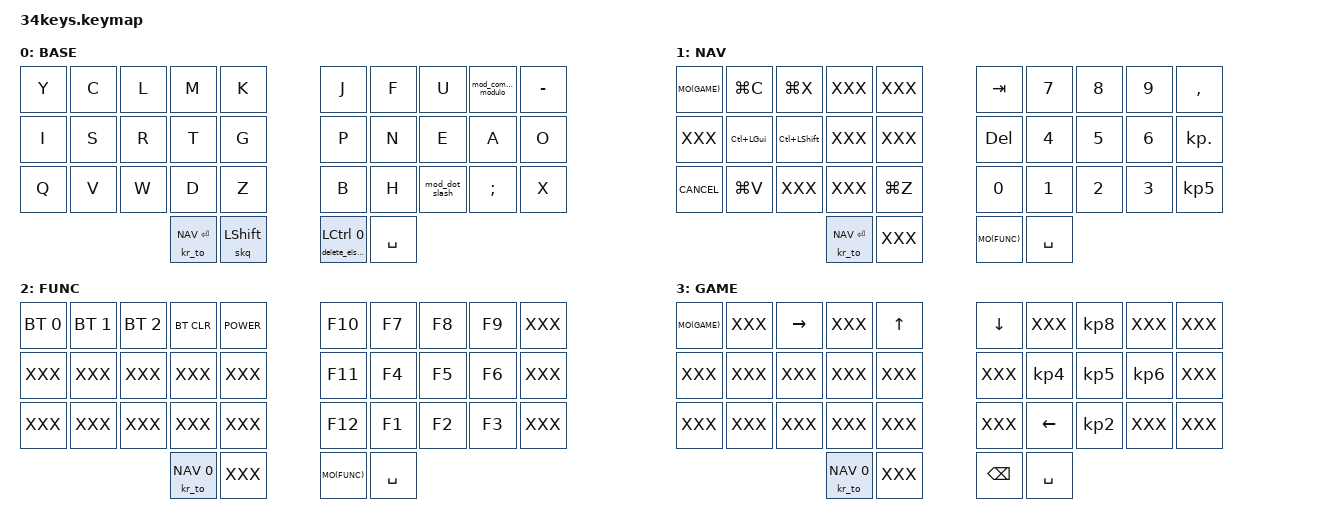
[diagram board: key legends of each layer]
#include <behaviors.dtsi>
#include <dt-bindings/zmk/keys.h>
#include <dt-bindings/zmk/bt.h>
#include <dt-bindings/zmk/outputs.h>
#include <dt-bindings/zmk/mouse.h>
#include <dt-bindings/zmk/mouse_settings.h>
#include "34keys.h"
#include "mouse_keys.dtsi"

&sk {
  release-after-ms = <STICKY_KEY_TIMEOUT>;
};

&caps_word {
  continue-list = <UNDERSCORE MINUS BACKSPACE>;
};

/ {

  combos {
    #include "combos.dtsi"
  };

  macros {
   #include "macros.dtsi"
  };

  behaviors {
    #include "behaviorsfs.dtsi"
  };

  keymap {
    compatible = "zmk,keymap";

    base_layer {
      label = "BASE";
      bindings = <
// ╭─────────────┬─────────────┬─────────────┬─────────────┬─────────────╮   ╭─────────────┬─────────────┬─────────────┬─────────────┬─────────────╮
        &kp Y         &kp C         &kp L         &kp M         &kp K             &kp J         &kp F         &kp U         &mod_comma_modulo	&kp MINUS
// ├─────────────┼─────────────┼─────────────┼─────────────┼─────────────┤   ├─────────────┼─────────────┼─────────────┼─────────────┼─────────────┤
        &kp I         &kp S         &kp R         &kp T         &kp G             &kp P         &kp N         &kp E         &kp A         &kp O
// ├─────────────┼─────────────┼─────────────┼─────────────┼─────────────┤   ├─────────────┼─────────────┼─────────────┼─────────────┼─────────────┤
        &kp Q         &kp V         &kp W         &kp D         &kp Z             &kp B         &kp H         &mod_dot_slash &kp SEMI      &kp X
// ╰─────────────┴─────────────┴─────────────┼─────────────┼─────────────┤   ├─────────────┼─────────────┼─────────────┴─────────────┴─────────────╯
                                                &kr_to NAV ENTER   &skq LSHIFT       &delete_else_hold LCTRL 0 &kp SPACE
//                                           ╰─────────────┴─────────────╯   ╰─────────────┴─────────────╯
      >;
    };

    nav_layer {
      label = "NAV";
      bindings = <
// ╭─────────────┬─────────────┬─────────────┬─────────────┬─────────────╮   ╭─────────────┬─────────────┬─────────────┬─────────────┬─────────────╮
        MO(GAME)     &kp LG(C)			&kp LG(X)           XXX			XXX 			&kp TAB       &kp N7         &kp N8        &kp N9         &kp COMMA
// ├─────────────┼─────────────┼─────────────┼─────────────┼─────────────┤   ├─────────────┼─────────────┼─────────────┼─────────────┼─────────────┤
        XXX          &kp LC(LGUI) 	&kp LC(LSHFT) XXX     		XXX 			&kp DEL       &kp N4         &kp N5        &kp N6         &kp KP_DOT
// ├─────────────┼─────────────┼─────────────┼─────────────┼─────────────┤   ├─────────────┼─────────────┼─────────────┼─────────────┼─────────────┤
        &kp K_CANCEL  &kp LG(V)			XXX       	  XXX           &kp LG(Z) 		    &kp N0        &kp N1         &kp N2        &kp N3         &kp KP_N5
// ╰─────────────┴─────────────┴─────────────┼─────────────┼─────────────┤   ├─────────────┼─────────────┼─────────────┴─────────────┴─────────────╯
                                                &kr_to NAV ENTER    XXX               MO(FUNC)      &kp SPACE
//                                           ╰─────────────┴─────────────╯   ╰─────────────┴─────────────╯
      >;
    };

func_layer {
      label = "FUNC";
      bindings = <
// ╭─────────────┬─────────────┬─────────────┬─────────────┬─────────────╮   ╭─────────────┬─────────────┬─────────────┬─────────────┬─────────────╮
        &bt BT_SEL 0  &bt BT_SEL 1  &bt BT_SEL 2  &bt BT_CLR    &kp C_POWER       &kp F10       &kp F7         &kp F8        &kp F9        XXX
// ├─────────────┼─────────────┼─────────────┼─────────────┼─────────────┤   ├─────────────┼─────────────┼─────────────┼─────────────┼─────────────┤
        XXX           XXX           XXX           XXX           XXX               &kp F11       &kp F4         &kp F5        &kp F6        XXX
// ├─────────────┼─────────────┼─────────────┼─────────────┼─────────────┤   ├─────────────┼─────────────┼─────────────┼─────────────┼─────────────┤
        XXX           XXX           XXX           XXX           XXX               &kp F12       &kp F1         &kp F2        &kp F3        XXX
// ╰─────────────┴─────────────┴─────────────┼─────────────┼─────────────┤   ├─────────────┼─────────────┼─────────────┴─────────────┴─────────────╯
                                                &kr_to NAV 0    XXX               MO(FUNC)      &kp SPACE
//                                           ╰─────────────┴─────────────╯   ╰─────────────┴─────────────╯
      >;
    };

    game_layer {
      label = "GAME";
      bindings = <
// ╭─────────────┬─────────────┬─────────────┬─────────────┬─────────────╮   ╭─────────────┬─────────────┬─────────────┬─────────────┬─────────────╮
        MO(GAME)      XXX           &kp RIGHT     XXX           &kp UP            &kp DOWN      XXX            &kp KP_N8    XXX            XXX
// ├─────────────┼─────────────┼─────────────┼─────────────┼─────────────┤   ├─────────────┼─────────────┼─────────────┼─────────────┼─────────────┤
        XXX           XXX           XXX           XXX           XXX               XXX           &kp KP_N4      &kp KP_N5    &kp KP_N6      XXX
// ├─────────────┼─────────────┼─────────────┼─────────────┼─────────────┤   ├─────────────┼─────────────┼─────────────┼─────────────┼─────────────┤
        XXX           XXX           XXX           XXX           XXX               XXX           &kp LEFT       &kp KP_N2    XXX            XXX
// ╰─────────────┴─────────────┴─────────────┼─────────────┼─────────────┤   ├─────────────┼─────────────┼─────────────┴─────────────┴─────────────╯
                                                &kr_to NAV 0    XXX               &kp BKSP      &kp SPACE
//                                           ╰─────────────┴─────────────╯   ╰─────────────┴─────────────╯
      >;
    };
  };
};
